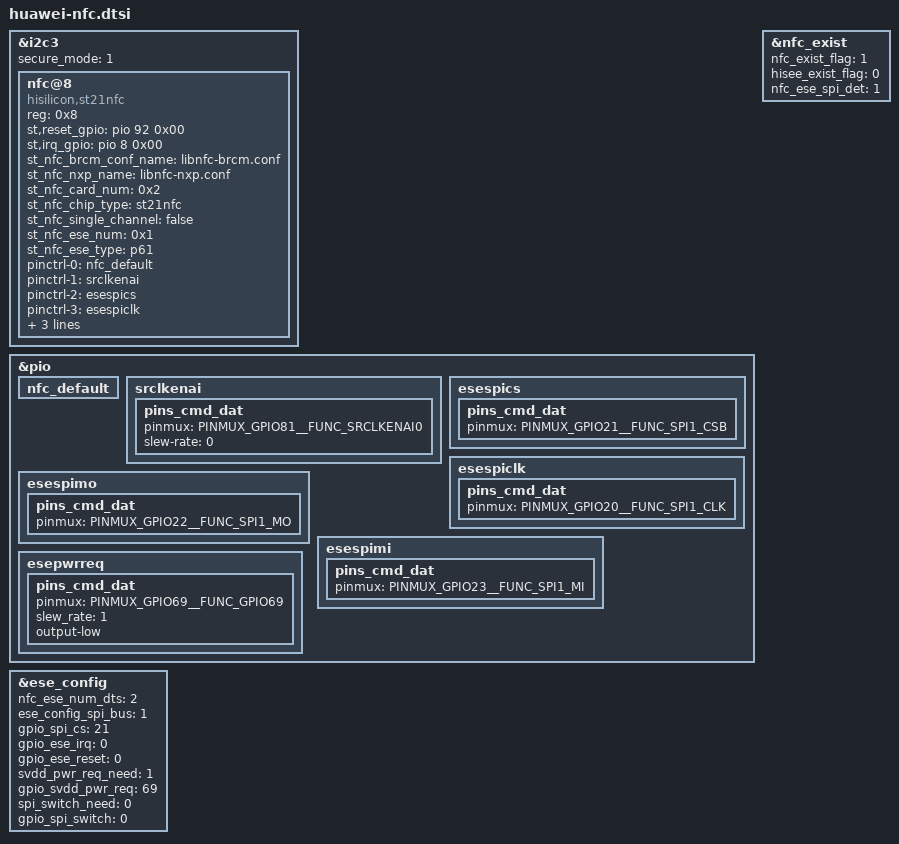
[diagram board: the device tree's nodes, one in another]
&i2c3 {
	secure_mode = <1>;
	nfc@8 {
		compatible = "hisilicon,st21nfc";
		status = "okay";
		reg = <0x8>;

		st,reset_gpio = <&pio 92 0x00>;
		st,irq_gpio = <&pio 8 0x00>;

		st_nfc_brcm_conf_name = "libnfc-brcm.conf";
		st_nfc_nxp_name = "libnfc-nxp.conf";
		st_nfc_card_num = <0x2>;
		st_nfc_chip_type = "st21nfc";
		st_nfc_single_channel = "false";
		st_nfc_ese_num = <0x1>;
		st_nfc_ese_type = "p61";
		pinctrl-names = "nfc_default","srclkenai","esespics","esespiclk","esespimo","esespimi","esepwrreq";
		pinctrl-0 = <&nfc_default>;
		pinctrl-1 = <&srclkenai>;
		pinctrl-2 = <&esespics>;
		pinctrl-3 = <&esespiclk>;
		pinctrl-4 = <&esespimo>;
		pinctrl-5 = <&esespimi>;
		pinctrl-6 = <&esepwrreq>;
	};
};

&pio {
	nfc_default: nfc_default {
	};

	srclkenai: srclkenai {
		pins_cmd_dat {
			pinmux = <PINMUX_GPIO81__FUNC_SRCLKENAI0>;
			slew-rate = <0>;
		};
	};
	esespics: esespics {
		pins_cmd_dat {
			pinmux = <PINMUX_GPIO21__FUNC_SPI1_CSB>;
		};
	};
	esespiclk: esespiclk {
		pins_cmd_dat {
			pinmux = <PINMUX_GPIO20__FUNC_SPI1_CLK>;
		};
	};
	esespimo: esespimo {
		pins_cmd_dat {
			pinmux = <PINMUX_GPIO22__FUNC_SPI1_MO>;
		};
	};
	esespimi: esespimi {
		pins_cmd_dat {
			pinmux = <PINMUX_GPIO23__FUNC_SPI1_MI>;
		};
	};
	esepwrreq: esepwrreq {
		pins_cmd_dat {
			pinmux = <PINMUX_GPIO69__FUNC_GPIO69>;
			slew_rate = <1>;
			output-low;
		};
	};
};

/*nfc*/
&nfc_exist {
	nfc_exist_flag = "1";
	hisee_exist_flag = "0";
	nfc_ese_spi_det = "1";
	status = "ok";
};

&ese_config {
	nfc_ese_num_dts = <2>;
	ese_config_spi_bus = <1>;
	gpio_spi_cs = <21>;
	gpio_ese_irq = <0>;
	gpio_ese_reset = <0>;
	svdd_pwr_req_need = <1>;
	gpio_svdd_pwr_req = <69>;
	spi_switch_need = <0>;
	gpio_spi_switch = <0>;
	status = "ok";
};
